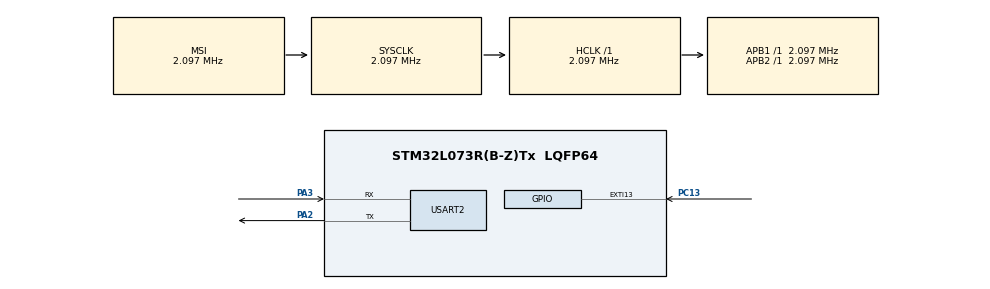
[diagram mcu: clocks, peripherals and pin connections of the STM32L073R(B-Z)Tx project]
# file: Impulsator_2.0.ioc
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Mcu.Family=STM32L0
Mcu.Name=STM32L073R(B-Z)Tx
Mcu.Package=LQFP64
NVIC.EXTI4_15_IRQn=true\:0\:0\:false\:false\:true\:true\:true\:true
NVIC.PVD_IRQn=true\:1\:0\:true\:false\:true\:true\:true\:true
NVIC.USART2_IRQn=true\:0\:0\:false\:false\:true\:true\:true\:true
PA13.GPIO_Label=TMS
PA13.Mode=Serial_Wire
PA13.Signal=SYS_SWDIO
PA14.GPIO_Label=TCK
PA14.Mode=Serial_Wire
PA14.Signal=SYS_SWCLK
PA2.GPIO_ModeDefaultPP=GPIO_MODE_AF_PP
PA2.GPIO_PuPd=GPIO_NOPULL
PA2.GPIO_Speed=GPIO_SPEED_FREQ_VERY_HIGH
PA2.Mode=Asynchronous
PA2.Signal=USART2_TX
PA3.GPIO_ModeDefaultPP=GPIO_MODE_AF_PP
PA3.GPIO_PuPd=GPIO_NOPULL
PA3.GPIO_Speed=GPIO_SPEED_FREQ_VERY_HIGH
PA3.Mode=Asynchronous
PA3.Signal=USART2_RX
PC13.Signal=GPXTI13
PC14-OSC32_IN.Mode=LSE-External-Oscillator
PC14-OSC32_IN.Signal=RCC_OSC32_IN
PC15-OSC32_OUT.Mode=LSE-External-Oscillator
PC15-OSC32_OUT.Signal=RCC_OSC32_OUT
PH0-OSC_IN.GPIO_Label=MCO
PH0-OSC_IN.Mode=HSE-External-Clock-Source
PH0-OSC_IN.Signal=RCC_OSC_IN
ProjectManager.HeapSize=0x200
ProjectManager.StackSize=0x400
ProjectManager.TargetToolchain=STM32CubeIDE
RCC.AHBFreq_Value=2097000
RCC.APB1Freq_Value=2097000
RCC.APB1TimFreq_Value=2097000
RCC.APB2Freq_Value=2097000
RCC.APB2TimFreq_Value=2097000
RCC.HCLKFreq_Value=2097000
RCC.HSE_VALUE=8000000
RCC.HSI16_VALUE=16000000
RCC.HSI48_VALUE=48000000
RCC.HSI_VALUE=16000000
RCC.MSI_VALUE=2097000
RCC.PLLSourceVirtual=RCC_PLLSOURCE_HSE
RCC.SYSCLKFreq_VALUE=2097000
RCC.Usart2ClockSelection=RCC_USART2CLKSOURCE_SYSCLK
RCC.VCOOutputFreq_Value=24000000
SYS.Mode=PWR_PVD_MODE_IT_RISING
SYS.PVDLevel=PWR_PVDLEVEL_6
USART2.VirtualMode-Asynchronous=VM_ASYNC
VP_SYS_V_PVD_IN.Mode=Mode_PVD_Int
board=NUCLEO-L073RZ

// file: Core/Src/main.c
/* USER CODE BEGIN Header */
/**
  ******************************************************************************
  * @file           : main.c
  * @brief          : Main program body
  ******************************************************************************
  * @attention
  *
  * Copyright (c) 2023 STMicroelectronics.
  * All rights reserved.
  *
  * This software is licensed under terms that can be found in the LICENSE file
  * in the root directory of this software component.
  * If no LICENSE file comes with this software, it is provided AS-IS.
  *
  ******************************************************************************
  */

/* USER CODE END Header */
#include "main.h"
#include "usart.h"
#include "gpio.h"

/* USER CODE BEGIN Includes */
#include <string.h>
#include <stdio.h>
#include <stdlib.h>
#include <ctype.h>
#include <stdbool.h>
#include "standby.h"
#include "tim6.h"
#include "flash.h"
/* USER CODE END Includes */

/* USER CODE BEGIN PD */
#define LINE_MAX_LENGTH 90
#define MAX_TOKENS 4
#define SIZE_OF_VARIABLE 10
#define PULSE_PORT GPIOA
#define PULSE_LOW ~(1U<<0) & ~(1U<<1) & ~(1U<<6)
#define PULSE_HIGH (1U<<0) | (1U<<1) | (1U<<6)
#define POWER_LED_PORT  GPIOB
#define POWER_LED_PIN  (1U<<3)
#define STATUS_LED_PORT GPIOB
#define STATUS_LED_PIN (1U<<5)
/* USER CODE END PD */

/* USER CODE BEGIN PM */
#define MAX_VALUE(a) (a<4294967295) ? 0 : 1
#define CHECK_ODR_IF_LOW (((PULSE_PORT->ODR & GPIO_ODR_OD0)&&(PULSE_PORT->ODR & GPIO_ODR_OD1)&&(PULSE_PORT->ODR & GPIO_ODR_OD6))? 1 : 0)
#define CHECK_DUTY_CYCLE_IF_GREATER_EQUAL_100 (pulse_parameter.config.duty_cycle>=100 ? 1 : 0)
/* USER CODE END PM */

/* USER CODE BEGIN PV */
enum STATE_OF_PROGRAM{
	RUNNING_INFI,
	RUNNING_N_TIMES,
	SAVE_DATA,
	READ_DATA,
	DISPLAY_DATA,
	DONE
}state;

typedef struct {
	uint32_t Adrr_numer_of_pulses;
	uint32_t Adrr_total_pulse_generated;
	uint32_t Adrr_Ton;
	uint32_t Adrr_Toff;
	uint32_t Adrr_freq;
	uint32_t Adrr_duty_cycle;
	uint32_t Adrr_if_infinitive;
} Adrress;

struct imp_config{
	uint32_t freq;
	uint32_t duty_cycle;
	uint32_t Ton;
	uint32_t Toff;
	uint32_t Period;
};

typedef struct {
	uint32_t numer_of_pulses;
	uint32_t total_pulse_generated;
	struct imp_config config;
	uint32_t if_infinity;
	uint32_t if_running;
} running_state;

typedef struct{
	uint8_t pvd;
	uint8_t save;
	uint8_t command_was_sent;
}flag;

Adrress Adrr_flash;
flag pulse_flag;
running_state pulse_parameter;

uint32_t* ptr_to_data_struct = (uint32_t*)&pulse_parameter;
uint8_t value;

static size_t size_of_config=sizeof(pulse_parameter)/sizeof(pulse_parameter.numer_of_pulses);
static char line_buffer[LINE_MAX_LENGTH + 1];
char* tokens[MAX_TOKENS];
static uint32_t line_length;
static char menu[]="\n\r---------------HOW TO USE---------------\n\rrun: Start a program\n\rread: Stop and read a variables\n\r"
				   "cont: To continue\n\r";
static char error[]="\n\rWrong key\n\r";
static char error_with_run[]="\r\nrun num freq duty cycle(max 99) or run oo(infinitive) freq duty cycle(max 99)\n\r "
							 "\n\r Where num mean how many pulses we want to generate, freq means frequency\n\r";
static char error_with_duty_cycle[]="\n\rToo high value of duty cycle\n\r";
static char error_with_lenght[]="Too long command";
/* USER CODE END PV */

void SystemClock_Config(void);
/* USER CODE BEGIN PFP */
/* USER CODE BEGIN PFP */
void STANDBY(void);
void MENU_USB(uint8_t data);
void display_menu(char table);
void PG_init(void);
void TIM6_init(void);
void GPIO_LEDS(void);
void Adrress_init(void);
void generate_pulse(void);
void read_data(void);
void display_data(void);
void save_data_to_flash(uint32_t Address, uint32_t* data, uint8_t size_of_config);
void erase_data_from_flash(uint32_t Address);
uint8_t if_equal_zero(running_state struct_of_pulse_config);
uint32_t read_data_from_flash(uint32_t Address);
uint32_t ASCII_TO_uint8_t(const char *table);
void splitString(const char* input_string, char** tokens);
void TIM6_IRQHandler(void);
void TIM6_Callback(void);
/* USER CODE END PFP */

/* USER CODE BEGIN 0 */
int __io_putchar(int ch)
{
    HAL_UART_Transmit(&huart2, (uint8_t*)&ch, 1, 0);\
    return 1;
}

void HAL_UART_RxCpltCallback(UART_HandleTypeDef *huart){
  if (huart == &huart2) {
	  MENU_USB(value);
	  HAL_UART_Receive_IT(&huart2, &value, 1);
	  HAL_UART_Transmit(&huart2, &value, 1, 0);
 }
}

void TIM6_Callback(void){
	if(pulse_parameter.if_running==1){
		STATUS_LED_PORT->ODR^=STATUS_LED_PIN;
	}
	else{
		STATUS_LED_PORT->ODR=STATUS_LED_PIN;
	}
}

void HAL_PWR_PVDCallback(void){
	static bool was_executed = false;
	if (was_executed) {
  		save_data_to_flash(Adrr_flash.Adrr_numer_of_pulses, ptr_to_data_struct,size_of_config);
  		STANDBY();
    }
    else{
    	was_executed=true;
    	pulse_flag.pvd=0;

    }
}

/* USER CODE END 0 */

int main(void)
{

  /* MCU Configuration--------------------------------------------------------*/

  /* Reset of all peripherals, Initializes the Flash interface and the Systick. */
  HAL_Init();

  /* USER CODE BEGIN Init */
  //PVD_init();
  PG_init();
  GPIO_LEDS();
  TIM6_init();
  Adrress_init();
  state=DONE;
  /* USER CODE END Init */

  /* Configure the system clock */
  SystemClock_Config();

  /* Initialize all configured peripherals */
  MX_GPIO_Init();
  MX_USART2_UART_Init();
  /* USER CODE BEGIN 2 */

  printf(menu);
  HAL_UART_Receive_IT(&huart2, &value, 1);
  /* USER CODE END 2 */

  /* Infinite loop */
  /* USER CODE BEGIN WHILE */
  while(1){
	  if(pulse_flag.pvd==0){
		  POWER_LED_PORT->ODR|=POWER_LED_PIN;
	  }
	  if(pulse_flag.command_was_sent==1){
		  display_menu(*line_buffer);
		  pulse_flag.command_was_sent=0;
	  }
	  switch(state){
	  	  case RUNNING_INFI:
	  		generate_pulse();
	  		break;
	  	  case RUNNING_N_TIMES:
	  		generate_pulse();
	  		(pulse_parameter.numer_of_pulses)--;
	  		if(pulse_parameter.numer_of_pulses>0 && pulse_parameter.if_running==1){
	  			state=RUNNING_N_TIMES;
	  		  }
	  		else{
	  			state=SAVE_DATA;
	  		  }
	  		break;
	  	  case SAVE_DATA:
	  		save_data_to_flash(Adrr_flash.Adrr_numer_of_pulses, ptr_to_data_struct,size_of_config);
	  		pulse_flag.save=1;
	  		HAL_Delay(100);
	  		state=READ_DATA;
	  		break;
	  	  case READ_DATA:
	  		read_data();
	  		state=DISPLAY_DATA;
	  		break;
	  	  case DISPLAY_DATA:
	  		display_data();
	  		state=DONE;
	  		break;
	  	  case DONE:
	  		break;
	  	  }
  }
    /* USER CODE END WHILE */

}

void SystemClock_Config(void)
{
  RCC_OscInitTypeDef RCC_OscInitStruct = {0};
  RCC_ClkInitTypeDef RCC_ClkInitStruct = {0};
  RCC_PeriphCLKInitTypeDef PeriphClkInit = {0};

  /** Configure the main internal regulator output voltage
  */
  __HAL_PWR_VOLTAGESCALING_CONFIG(PWR_REGULATOR_VOLTAGE_SCALE1);

  /** Initializes the RCC Oscillators according to the specified parameters
  * in the RCC_OscInitTypeDef structure.
  */
  RCC_OscInitStruct.OscillatorType = RCC_OSCILLATORTYPE_MSI;
  RCC_OscInitStruct.MSIState = RCC_MSI_ON;
  RCC_OscInitStruct.MSICalibrationValue = 0;
  RCC_OscInitStruct.MSIClockRange = RCC_MSIRANGE_5;
  RCC_OscInitStruct.PLL.PLLState = RCC_PLL_NONE;
  if (HAL_RCC_OscConfig(&RCC_OscInitStruct) != HAL_OK)
  {
    Error_Handler();
  }

  /** Initializes the CPU, AHB and APB buses clocks
  */
  RCC_ClkInitStruct.ClockType = RCC_CLOCKTYPE_HCLK|RCC_CLOCKTYPE_SYSCLK
                              |RCC_CLOCKTYPE_PCLK1|RCC_CLOCKTYPE_PCLK2;
  RCC_ClkInitStruct.SYSCLKSource = RCC_SYSCLKSOURCE_MSI;
  RCC_ClkInitStruct.AHBCLKDivider = RCC_SYSCLK_DIV1;
  RCC_ClkInitStruct.APB1CLKDivider = RCC_HCLK_DIV1;
  RCC_ClkInitStruct.APB2CLKDivider = RCC_HCLK_DIV1;

  if (HAL_RCC_ClockConfig(&RCC_ClkInitStruct, FLASH_LATENCY_0) != HAL_OK)
  {
    Error_Handler();
  }
  PeriphClkInit.PeriphClockSelection = RCC_PERIPHCLK_USART2;
  PeriphClkInit.Usart2ClockSelection = RCC_USART2CLKSOURCE_SYSCLK;
  if (HAL_RCCEx_PeriphCLKConfig(&PeriphClkInit) != HAL_OK)
  {
    Error_Handler();
  }
}

/* USER CODE BEGIN 4 */

void GPIO_LEDS(void){
	RCC->IOPENR |= RCC_IOPENR_GPIOBEN;

	STATUS_LED_PORT->MODER &= ((STATUS_LED_PORT->MODER & ~(GPIO_MODER_MODE5)) | (GPIO_MODER_MODE5_0));
	POWER_LED_PORT->MODER &= ((POWER_LED_PORT->MODER & ~(GPIO_MODER_MODE3)) | (GPIO_MODER_MODE3_0));
}

void PG_init(void){
	RCC->IOPENR  |= RCC_IOPENR_GPIOAEN;

	PULSE_PORT -> MODER = (GPIO_MODER_MODE0_0)|(GPIOA->MODER & ~GPIO_MODER_MODE0);
	PULSE_PORT -> MODER = (GPIO_MODER_MODE1_0)|(GPIOA->MODER & ~GPIO_MODER_MODE1);
	PULSE_PORT -> MODER = (GPIO_MODER_MODE6_0)|(GPIOA->MODER & ~GPIO_MODER_MODE6);

	PULSE_PORT-> BSRR |= PULSE_HIGH;
}

void Adrress_init(void){
	Adrr_flash.Adrr_numer_of_pulses=0x0800FFA0;
	Adrr_flash.Adrr_total_pulse_generated=0x0800FFA4;
	Adrr_flash.Adrr_Ton=0x0800FFB0;
	Adrr_flash.Adrr_Toff=0x0800FFB4;
	Adrr_flash.Adrr_freq=0x0800FFA8;
	Adrr_flash.Adrr_duty_cycle=0x0800FFAC;
	Adrr_flash.Adrr_if_infinitive=0x0800FFBC;
}

void MENU_USB(uint8_t value){
 		if (value == '\r' || value == '\n') {
 			pulse_flag.command_was_sent=1;
		}
 		else if (value == '\177') {
 			if (line_length > 0) {
				line_length--;
				printf("\177 \177");
 		   }
 		}
		else {
			if (line_length >= LINE_MAX_LENGTH) {
				line_length = 0;
				printf(error);
				printf(error_with_lenght);
			}
			line_buffer[line_length++] = value;
		}
}

void display_menu(char table){
	int if_variable_is_digital;
	char * if_user_choose_infi;
	if (line_length > 0) {
		line_buffer[line_length] = '\0';
			if (strncmp(line_buffer, "run",3) == 0) {
				if(pulse_parameter.if_running==1){
					printf("\n\rA program is working, to enter new parameters use stop first\n\r");
				}
				else{
					splitString(line_buffer, tokens);
					if_user_choose_infi=strpbrk(tokens[1], "oo");
					if((!(if_user_choose_infi==NULL)) && state!=RUNNING_N_TIMES){
						for(int i=2;i<MAX_TOKENS;i++){
							if_variable_is_digital=1;
							for(int j=0;j<strlen(tokens[i]);j++){
								if(!isdigit((unsigned char)tokens[i][j])){
									if_variable_is_digital=0;
								}
							}
							if(if_variable_is_digital==0){
								break;
							}
						}
						if(if_variable_is_digital!=0){
							pulse_parameter.if_infinity=1;
							pulse_parameter.config.freq=ASCII_TO_uint8_t(tokens[2]);
							pulse_parameter.config.duty_cycle=ASCII_TO_uint8_t(tokens[3]);
								if(if_equal_zero(pulse_parameter)){
									printf(error_with_run);
								}
								else if(CHECK_DUTY_CYCLE_IF_GREATER_EQUAL_100){
									printf(error_with_duty_cycle);
								}
								else{
									pulse_parameter.config.Period=(float)(1000/pulse_parameter.config.freq);
									pulse_parameter.config.Ton=(float)((pulse_parameter.config.Period*pulse_parameter.config.duty_cycle)/100);
									pulse_parameter.config.Toff=pulse_parameter.config.Period-pulse_parameter.config.Ton;
									pulse_parameter.if_running=1;
									state=RUNNING_INFI;
									erase_data_from_flash(Adrr_flash.Adrr_numer_of_pulses);
								}
						}
						else{
							printf(error_with_run);
						}
					}
					else if (if_user_choose_infi==NULL && state!=RUNNING_INFI){
						for(int i=1;i<MAX_TOKENS;i++){
							if_variable_is_digital=1;
							for(int j=0;j<strlen(tokens[i]);j++){
								if(!isdigit((unsigned char)tokens[i][j])){
									if_variable_is_digital=0;
								}
							}
							if(if_variable_is_digital==0){
								break;
							}
						}
							if(if_variable_is_digital!=0){
								pulse_parameter.if_infinity=0;
								pulse_parameter.numer_of_pulses=ASCII_TO_uint8_t(tokens[1]);
								pulse_parameter.config.freq=ASCII_TO_uint8_t(tokens[2]);
								pulse_parameter.config.duty_cycle=ASCII_TO_uint8_t(tokens[3]);
								if(if_equal_zero(pulse_parameter)){
									printf(error_with_run);
								}
								else if(CHECK_DUTY_CYCLE_IF_GREATER_EQUAL_100){
									printf(error_with_duty_cycle);
								}
								else{
									pulse_parameter.config.Period=(float)(1000/pulse_parameter.config.freq);
									pulse_parameter.config.Ton=(float)((pulse_parameter.config.Period*pulse_parameter.config.duty_cycle)/100);
									pulse_parameter.config.Toff=pulse_parameter.config.Period-pulse_parameter.config.Ton;
									erase_data_from_flash(Adrr_flash.Adrr_numer_of_pulses);
									pulse_parameter.if_running=1;
									state=RUNNING_N_TIMES;
								}
							}
							else{
								printf(error_with_run);
							}
					}
					for (int i = 0; i < sizeof(tokens) / sizeof(tokens[0]); i++) {
						 free(tokens[i]);
					}
				}
		}
		else if (strcmp(line_buffer, "read") == 0){
			pulse_parameter.if_running=0;
			state=SAVE_DATA;
		}
		else if (strcmp(line_buffer, "cont") == 0){
			read_data();
			erase_data_from_flash(Adrr_flash.Adrr_numer_of_pulses);
			if(pulse_parameter.if_infinity==0){
            	if(pulse_parameter.numer_of_pulses!=0){
            		pulse_parameter.if_running=1;
					state=RUNNING_N_TIMES;
            	}
            	else{
            		state=DONE;
            	}
			}
			else if(pulse_parameter.if_infinity==1){
				pulse_parameter.if_running=1;
				state=RUNNING_INFI;
			}
		}
		else {
			printf(error);
			printf(menu);
		}
		printf("\n\r");
		for(int i;i<line_length;i++){
			line_buffer[i]='\0';
			}
		line_length = 0;
	}
	else{
		printf(error);
		printf(menu);
	}
}

uint32_t ASCII_TO_uint8_t(const char *table){
	uint32_t result = 0;
	uint32_t numeric_value=0;
    int size = SIZE_OF_VARIABLE;
    for (int i = 0; i < size; i++) {
    	if(table[i]==' ' || table[i]=='\0'){
    		break;
    	}
    	else{
        	numeric_value = table[i] - '0';
            result = result * 10 + numeric_value;
    	}
    }
    return result;
}

void splitString(const char* input_string, char** tokens) {
	const char delimiters[] = " \r\n";
    char* copy_of_input = strdup(input_string);
    char* token = strtok(copy_of_input, delimiters);

    int token_count = 0;
    while (token != NULL && token_count < MAX_TOKENS) {
        tokens[token_count] = strdup(token);
        token = strtok(NULL, delimiters);
        token_count++;
    }
    free(copy_of_input);
}

void generate_pulse(void){
	  PULSE_PORT->BSRR = PULSE_LOW;
	  while(CHECK_ODR_IF_LOW){}
	  HAL_Delay((uint32_t)pulse_parameter.config.Ton);
	  PULSE_PORT->BSRR |= PULSE_HIGH;
	  while(!CHECK_ODR_IF_LOW){}
	  HAL_Delay((uint32_t)pulse_parameter.config.Toff);
	  (pulse_parameter.total_pulse_generated)++;
}

void read_data(void){
	pulse_parameter.if_infinity=read_data_from_flash(Adrr_flash.Adrr_if_infinitive);
	pulse_parameter.numer_of_pulses=read_data_from_flash(Adrr_flash.Adrr_numer_of_pulses);
	pulse_parameter.total_pulse_generated=read_data_from_flash(Adrr_flash.Adrr_total_pulse_generated);
	pulse_parameter.config.Ton=read_data_from_flash(Adrr_flash.Adrr_Ton);
	pulse_parameter.config.Toff=read_data_from_flash(Adrr_flash.Adrr_Toff);
	pulse_parameter.config.freq=read_data_from_flash(Adrr_flash.Adrr_freq);
	pulse_parameter.config.duty_cycle=read_data_from_flash(Adrr_flash.Adrr_duty_cycle);
}

uint8_t if_equal_zero(running_state struct_of_pulse_config){
	uint8_t result;
	if(struct_of_pulse_config.if_infinity && (struct_of_pulse_config.config.freq==0 || struct_of_pulse_config.config.duty_cycle==0)){
			result = 1;
	}
	else if(MAX_VALUE(struct_of_pulse_config.numer_of_pulses) || struct_of_pulse_config.numer_of_pulses==0|| struct_of_pulse_config.config.freq==0 || struct_of_pulse_config.config.duty_cycle==0){
		result = 1;
	}
	else{
		result = 0;
	}
	return result;
}

void display_data(void){
	  if(pulse_parameter.if_infinity==1){
		 sprintf(line_buffer,"User chose to generate infinity pulses,Total pulses:%lu,Ton:%lu,Toff:%lu,Freq:%lu,Duty_cycle:%lu\r\n",pulse_parameter.total_pulse_generated,pulse_parameter.config.Ton,pulse_parameter.config.Toff,pulse_parameter.config.freq,pulse_parameter.config.duty_cycle);
	  }
	  else{
		  sprintf(line_buffer,"How many pulses left:%lu,Total pulses:%lu,Ton:%lu,Toff:%lu,Freq:%lu,Duty cycle:%lu\r\n",pulse_parameter.numer_of_pulses,pulse_parameter.total_pulse_generated,pulse_parameter.config.Ton,pulse_parameter.config.Toff,pulse_parameter.config.freq,pulse_parameter.config.duty_cycle);
	  }
	  HAL_UART_Transmit(&huart2, (uint8_t*)line_buffer, strlen(line_buffer), 50);
	  for(int i;i<strlen(line_buffer);i++){
		  line_buffer[i]='\0';
	  }
	  for(int i =0;i<size_of_config;i++){
			*(ptr_to_data_struct+i)=0;
	  }
}

void TIM6_IRQHandler(void){
	TIM6->SR &=~TIM_SR_UIF;
	if(pulse_flag.pvd==0){
		TIM6_Callback();
	}
}

/* USER CODE END 4 */

void Error_Handler(void)
{
  __disable_irq();
  while (1)
  {
  }
}
